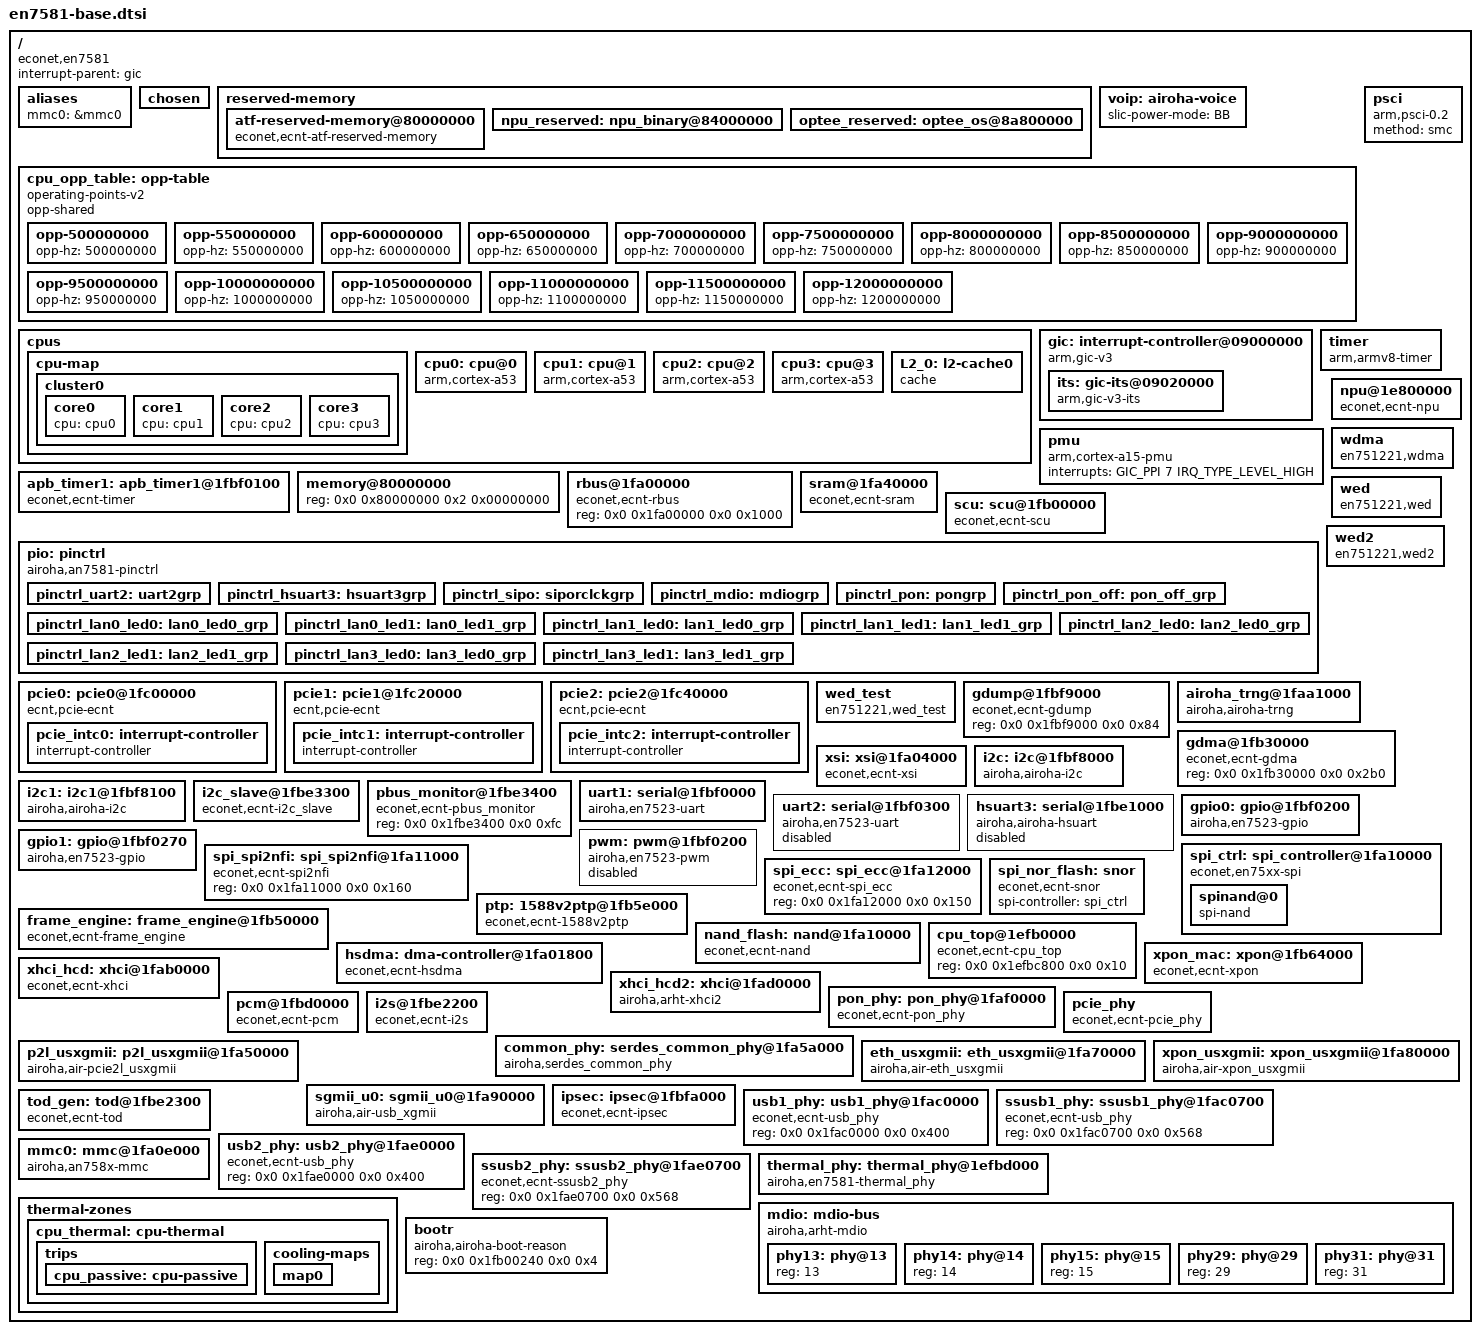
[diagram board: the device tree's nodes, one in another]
#include <dt-bindings/interrupt-controller/irq.h>
#include <dt-bindings/interrupt-controller/arm-gic.h>
#include <dt-bindings/gpio/gpio.h>
#include <dt-bindings/thermal/thermal.h>

/dts-v1/;

/ {
	compatible = "econet,en7581";
	interrupt-parent = <&gic>;
	#address-cells = <2>;
	#size-cells = <2>;

	aliases {
		mmc0 = &mmc0;
	};

	chosen {
		// --- onu_type ---
		// xPON ONU Type, 0--unknown, 1--SFU, 2--HGU, [7:4], 0x0--Auto, 0x1:GPON, 0x2:EPON, 0x3:XEPON_10G_1G,
		// 0x4:XEPON_10G_10G, 0x5:XEPON_1G_1G, 0x6:XGPON, 0x7:XGSPON...
		//
		// --- qdma_init ---
		// EN7580 QDMA init setting
		// [1:0], 0x0--qdma_lan payload size 2k, 0x1--qdma_lan 1k, 0x2--qdma_lan 512, 0x3--qdma_lan 256
		// [2], reserve
		// [3], 0x0--qdma_lan dscp in DRAM, 0x1--qdma_lan dscp in SRAM
		// [5:4], 0x0--qdma_wan payload size 2k, 0x1--qdma_wan 1k, 0x2--qdma_wan 512, 0x3--qdma_wan 256
		// [6], reserve
		// [7], 0x0--qdma_wan dscp in DRAM, 0x1--qdma_wan dscp in SRAM
		// default set: qdma_lan in SRAM, 256Byte payload; qdma_wan in DRAM, 256Byte payload
		// [8], 0 -- Wan(GDM2,PON/ATM/PTM..) slow path  1 -- fast path
		// [9], 0 -- Lan(GDM1,GSW) slow path  1 -- fast path
		// [10], 0 -- XSI PCIE0 slow path  1 -- fast path
		// [11], 0 -- XSI PCIE1 slow path  1 -- fast path
		// [12], 0 -- XSI USB slow path  1 -- fast path
		// [13], 0 -- XSI ETHER slow path  1 -- fast path
		// [14], 0 -- XSI PON slow path  1 -- fast path
		// [15], 0 -- XSI PCIE0 not care   1 -- direct to GDM
		// [16], 0 -- XSI PCIE1 not care   1 -- direct to GDM
		// [17], 0 -- XSI USB not care   1 -- direct to GDM
		// [18], 0 -- XSI ETHER not care   1 -- direct to GDM
		// [19], 0 -- XSI PON not care   1 -- direct to GDM
		//
		// --- serdes_pon ---
		// PON Serdes selection setting, serdes_sel is hex value
		// first digit is etherLAN or etherWAN select
		// 0: for NONE
		// 1: for etherLAN
		// 2: for etherWAN
		// second digit is serdes interface select
		// 0: for PON
		// 1: for XFI
		// 2: for USXGMII
		// 3: for HSGMII
		// 4: for PD(power down serdes)
		//
		// --- serdes_ethernet ---
		// Ethernet Serdes selection setting, serdes_sel is hex value
		// first digit is etherLAN or etherWAN select
		// 0: for NONE
		// 1: for etherLAN
		// 2: for etherWAN
		// second digit is serdes interface select
		// 0: for XFI
		// 1: for USXGMII
		// 2: for HSGMII
		// 3: for 5G BaseR
		// 4: for PD(power down serdes)
		//
		// --- serdes_wifi1 ---
		// WiFi_1 Serdes selection setting, serdes_sel is hex value
		// first digit is etherLAN or etherWAN select
		// 0: for NONE
		// 1: for etherLAN
		// 2: for etherWAN
		// second digit is serdes interface select
		// 0: for PCIE0 2-LANE
		// 1: for PCIE0 1-LANE
		// 2: for HSGMII
		// 3: for USXGMII
		// 4: for XFI
		// 5: for PD(power down serdes)
		//
		// --- serdes_wifi2 ---
		// WiFi_2 Serdes selection setting, serdes_sel is hex value
		// first digit is etherLAN or etherWAN select
		// 0: for NONE
		// 1: for etherLAN
		// 2: for etherWAN
		// second digit is serdes interface select
		// 0: for PCIE0 2-LANE
		// 1: for PCIE1 1-LANE
		// 2: for HSGMII
		// 3: for USXGMII
		// 4: for XFI
		// 5: for PD(power down serdes)
		//
		// --- serdes_usb1 ---
		// USB_1 Serdes selection setting, serdes_sel is hex value
		// first digit is etherLAN or etherWAN select
		// 0: for NONE
		// 1: for etherLAN
		// 2: for etherWAN
		// second digit is serdes interface select
		// 0: for USB 3.0 MAC
		// 1: for HSGMII
		// 2: for PD(power down serdes)
		//
		// --- serdes_usb2 ---
		// USB_2 Serdes selection setting, serdes_sel is hex value
		// first digit is etherLAN or etherWAN select
		// 0: for NONE
		// 1: for etherLAN
		// 2: for etherWAN
		// second digit is serdes interface select
		// 0: for USB 3.0 MAC
		// 1: for PCIE2 1-LANE
		// 2: for PD(power down serdes)

		bootargs = "console=ttyS0,115200n8 qdma_init=bb onu_type=72 serdes_ethernet=112 serdes_wifi1=01 serdes_wifi2=01 serdes_usb1=00 serdes_usb2=02 serdes_pon=00";
		stdout-path = &uart1;
	};

	reserved-memory {
		#address-cells = <2>;
		#size-cells = <2>;
		ranges;

		atf-reserved-memory@80000000 {
			compatible = "econet,ecnt-atf-reserved-memory";
			no-map;
			reg = <0x0 0x80000000 0x0 0x40000>;
		};

		npu_reserved: npu_binary@84000000 {
			no-map;
			reg = <0x0 0x84000000 0x0 0x100000>;
		};

		optee_reserved: optee_os@8a800000 {
			no-map;
			reg = <0x0 0x8a800000 0x0 0x800000>;
		};

		/* pstore memory reservations */
		#include "en7581-pstore.dtsi"

	};

	voip: airoha-voice {
		// -----------------------------------------------------
		// Slic power mode
		// -----------------------------------------------------
		// Possible values:
		//   BB		- Buck Boost
		//   IB		- Inverting Buck Boost
		//   TB		- Buck-Boost fixed tracker AKA 'Tracker Buck Boost'
		//
		// Notes:
		//   1) If slic power mode set to other non-empty value,
		//      slic modules will NOT be probed/loaded.
		//   2) If slic power mode is not set or set to empty
		//      string then "BB" mode will be used as default
		//   3) voip_loader command line options will override
		//      DTS settings.
		// -----------------------------------------------------
		slic-power-mode = "BB";
	};

	cpu_opp_table: opp-table {
		compatible = "operating-points-v2";
		opp-shared;

		opp-500000000 {
			opp-hz = /bits/ 64 <500000000>;
		};

		opp-550000000 {
			opp-hz = /bits/ 64 <550000000>;
		};

		opp-600000000 {
			opp-hz = /bits/ 64 <600000000>;
		};

		opp-650000000 {
			opp-hz = /bits/ 64 <650000000>;
		};

		opp-7000000000 {
			opp-hz = /bits/ 64 <700000000>;
		};

		opp-7500000000 {
			opp-hz = /bits/ 64 <750000000>;
		};

		opp-8000000000 {
			opp-hz = /bits/ 64 <800000000>;
		};

		opp-8500000000 {
			opp-hz = /bits/ 64 <850000000>;
		};

		opp-9000000000 {
			opp-hz = /bits/ 64 <900000000>;
		};

		opp-9500000000 {
			opp-hz = /bits/ 64 <950000000>;
		};

		opp-10000000000 {
			opp-hz = /bits/ 64 <1000000000>;
		};

		opp-10500000000 {
			opp-hz = /bits/ 64 <1050000000>;
		};

		opp-11000000000 {
			opp-hz = /bits/ 64 <1100000000>;
		};

		opp-11500000000 {
			opp-hz = /bits/ 64 <1150000000>;
		};

		opp-12000000000 {
			opp-hz = /bits/ 64 <1200000000>;
		};
	};

	psci {
		compatible = "arm,psci-0.2";
		method = "smc";
	};

	cpus {
		#address-cells = <1>;
		#size-cells = <0>;

		cpu-map {
			cluster0 {
				core0 {
					cpu = <&cpu0>;
				};
				core1 {
					cpu = <&cpu1>;
				};
				core2 {
					cpu = <&cpu2>;
				};
				core3 {
					cpu = <&cpu3>;
				};
			};
		};

		cpu0: cpu@0 {
			device_type = "cpu";
			compatible = "arm,cortex-a53";
			reg = <0x0>;
			operating-points-v2 = <&cpu_opp_table>;
			enable-method = "psci";
			clock-frequency = <80000000>;
			next-level-cache = <&L2_0>;
			#cooling-cells = <2>;
		};

		cpu1: cpu@1 {
			device_type = "cpu";
			compatible = "arm,cortex-a53";
			reg = <0x1>;
			operating-points-v2 = <&cpu_opp_table>;
			enable-method = "psci";
			clock-frequency = <80000000>;
			next-level-cache = <&L2_0>;
			#cooling-cells = <2>;
		};

		cpu2: cpu@2 {
			device_type = "cpu";
			compatible = "arm,cortex-a53";
			reg = <0x2>;
			operating-points-v2 = <&cpu_opp_table>;
			enable-method = "psci";
			clock-frequency = <80000000>;
			next-level-cache = <&L2_0>;
			#cooling-cells = <2>;
		};

		cpu3: cpu@3 {
			device_type = "cpu";
			compatible = "arm,cortex-a53";
			reg = <0x3>;
			operating-points-v2 = <&cpu_opp_table>;
			enable-method = "psci";
			clock-frequency = <80000000>;
			next-level-cache = <&L2_0>;
			#cooling-cells = <2>;
		};

		L2_0: l2-cache0 {
			compatible = "cache";
		};
	};

	gic: interrupt-controller@09000000 {
		compatible = "arm,gic-v3";
		interrupt-controller;
		#interrupt-cells = <3>;
		#address-cells = <1>;
		#size-cells = <1>;
		reg = <0x0 0x09000000 0x0 0x20000>,
		      <0x0 0x09080000 0x0 0x80000>;
		interrupts = <GIC_PPI 9 IRQ_TYPE_LEVEL_LOW>;

		its: gic-its@09020000 {
			compatible = "arm,gic-v3-its";
			msi-controller;
			#msi-cell = <1>;
			reg = <0x0 0x090200000 0x0 0x20000>;
		};
	};


	timer {
		compatible = "arm,armv8-timer";
		interrupt-parent = <&gic>;
		interrupts = <GIC_PPI 13 (GIC_CPU_MASK_SIMPLE(4) | IRQ_TYPE_LEVEL_LOW)>,
			     <GIC_PPI 14 (GIC_CPU_MASK_SIMPLE(4) | IRQ_TYPE_LEVEL_LOW)>,
			     <GIC_PPI 11 (GIC_CPU_MASK_SIMPLE(4) | IRQ_TYPE_LEVEL_LOW)>,
			     <GIC_PPI 10 (GIC_CPU_MASK_SIMPLE(4) | IRQ_TYPE_LEVEL_LOW)>;
		clock-frequency = <25000000>;
	};

	pmu {
		//compatible = "arm,armv8-pmuv3";
		compatible = "arm,cortex-a15-pmu";
		interrupts = <GIC_PPI 7 IRQ_TYPE_LEVEL_HIGH>;
	};

	npu@1e800000 {
		compatible = "econet,ecnt-npu";
		reg = <0x0 0x1e800000 0x0 0x78000>,	//NPU 480K SRAM
		      <0x0 0x1e900000 0x0 0x313000>;	//NPU 32K SRAM, registers
		memory-region = <&npu_reserved>;
		interrupts = <GIC_SPI 118 IRQ_TYPE_LEVEL_HIGH>,
			     <GIC_SPI 119 IRQ_TYPE_LEVEL_HIGH>,
			     <GIC_SPI 120 IRQ_TYPE_LEVEL_HIGH>,
			     <GIC_SPI 121 IRQ_TYPE_LEVEL_HIGH>,
			     <GIC_SPI 122 IRQ_TYPE_LEVEL_HIGH>,
			     <GIC_SPI 123 IRQ_TYPE_LEVEL_HIGH>,
			     <GIC_SPI 125 IRQ_TYPE_LEVEL_HIGH>,	//mbox2host irq
			     <GIC_SPI 103 IRQ_TYPE_LEVEL_HIGH>,	//npu timer0 wdog intr
			     <GIC_SPI 109 IRQ_TYPE_LEVEL_HIGH>,	//npu timer1 wdog intr
			     <GIC_SPI 113 IRQ_TYPE_LEVEL_HIGH>,	//npu timer2 wdog intr
			     <GIC_SPI 117 IRQ_TYPE_LEVEL_HIGH>,	//npu timer3 wdog intr
			     <GIC_SPI 134 IRQ_TYPE_LEVEL_HIGH>,	//npu timer4 wdog intr
			     <GIC_SPI 135 IRQ_TYPE_LEVEL_HIGH>,	//npu timer5 wdog intr
			     <GIC_SPI 136 IRQ_TYPE_LEVEL_HIGH>,	//npu timer6 wdog intr
			     <GIC_SPI 137 IRQ_TYPE_LEVEL_HIGH>;	//npu timer7 wdog intr
	};

	apb_timer1: apb_timer1@1fbf0100 {
		compatible = "econet,ecnt-timer";
		reg = <0x0 0x1fbf0100 0x0 0x40>;
		interrupts = <GIC_SPI 20 IRQ_TYPE_LEVEL_HIGH>,
			     <GIC_SPI 21 IRQ_TYPE_LEVEL_HIGH>,
			     <GIC_SPI 22 IRQ_TYPE_LEVEL_HIGH>,
			     <GIC_SPI 25 IRQ_TYPE_LEVEL_HIGH>;
	};

	memory@80000000 {
		device_type = "memory";
		reg = <0x0 0x80000000 0x2 0x00000000>;
	};

	rbus@1fa00000 {
		compatible = "econet,ecnt-rbus";
		reg = <0x0 0x1fa00000 0x0 0x1000>;		//RBus Core
	};

	sram@1fa40000 {
		compatible = "econet,ecnt-sram";
		reg = <0x0 0x1fa40000 0x0 0x8000>,		//GDMP SRAM
		      <0x0 0x08000000 0x0 0x40000>,		//L2C SRAM (only for CPU internal access)
		      <0x0 0x1EFC0000 0x0 0x40000>,		//L2C SRAM (only for CPU/NPU/GDMA/SPI/Crypto/WOE external access via pbus)
		      <0x0 0x1E880000 0x0 0x40000>,		//L2C SRAM (only for CPU/NPU/HSDMA/PCIE external access via npu_rbus)
		      <0x0 0x1fbe3000 0x0 0x200>;		//I2C_SLAVE SRAM
	};

	scu: scu@1fb00000 {
		bootph-all;
		compatible = "econet,ecnt-scu";
			// ------------------------------------------------------------
			// WARNING:
			// ------------------------------------------------------------
			//   1) [dirty hack] NP SCU iomem region length was reduced
			//	to avoid conflicts with "airoha-boot-reason" driver. This
			//	does NOT breaks "ecnt-scu" driver because mapping of the
			//	iomem area actually provide access not only to the
			//	specified area, but to the whole page, so all regs are
			//	still accessible.
			//   2) Actual NP SCU iomem area is:
			//	  <0x1fb00000 0x960>,	//NP SCU
			// ------------------------------------------------------------
		reg = <0x0 0x1fb00000 0x0 0x4>,		//NP SCU
			// ------------------------------------------------------------
			// WARNING:
			// ------------------------------------------------------------
			//   1) [dirty hack] Chip SCU iomem region length was reduced
			//	to avoid conflicts with "en7523-pinctrl" driver. This
			//	does NOT breaks "ecnt-scu" driver because mapping of the
			//	iomem area actually provide access not only to the
			//	specified area, but to the whole page, so all regs are
			//	still accessible.
			//   2) Function is_pinctrl_reg() was added to "ecnt-scu" driver
			//	to check access and prevent writing to pinctrl registers.
			//	Please keep in sync this function with "en7523-pinctrl"
			//	driver.
			//   3) Actual Chip SCU iomem area is:
			//	  <0x1fa20000 0x360>,	//CHIP SCU
			// ------------------------------------------------------------
			<0x0 0x1fa20000 0x0 0x4>,		//CHIP SCU
			<0x0 0x1fa2FF30 0x0 0x10>;		//Rbus clk ctl for FPGA
		interrupts = <GIC_SPI 47 IRQ_TYPE_LEVEL_HIGH>;
	};

	pio: pinctrl {
		compatible = "airoha,an7581-pinctrl";
		// --------------------------------------------------------------------
		// WARNING:
		// --------------------------------------------------------------------
		//   1) iomem regions used by this driver overlaps with iomem region
		//	used by "ecnt-scu" driver. Dirty hack (see scu@1fb00000 dts
		//	section) was introduced to make "ecnt-scu" and "an7581-pinctrl"
		//	coexisting.
		//   2) Please keep in sync iomem areas used by this driver with
		//	is_pinctrl_reg() function from the "ecnt-scu" driver.
		// --------------------------------------------------------------------
		reg = <0x0 0x1fa20214 0x0 0x20>, /* IOMUX Control Registers */
			<0x0 0x1fa2001C 0x0 0x18>, /* IO TX Driving Control Registers */
			<0x0 0x1fa20044 0x0 0x18>, /* IO Pull up/down Control Registers */
			<0x0 0x1fa2027C 0x0 0x8>;  /* LED Mapping Register */

		pinctrl_uart2: uart2grp {
			function = "uart2";
			groups = "uart2_grp";
		};

		pinctrl_hsuart3: hsuart3grp {
			function = "hsuart3";
			groups = "hsuart3_grp";
		};

		pinctrl_sipo: siporclckgrp {
			function = "sipo_rclk";
			groups = "sipo_rclk_grp";
		};

		pinctrl_mdio: mdiogrp {
			function = "mdio";
			groups = "mdio_grp";
		};

		pinctrl_pon: pongrp {
			function = "pon0";
			groups = "pon0_grp";
		};

		pinctrl_pon_off: pon_off_grp {
			function = "pon0_off";
			groups = "pon0_grp";
		};

		pinctrl_lan0_led0: lan0_led0_grp {
			function = "lan0_led0";
			groups = "lan0_led0_grp";
		};

		pinctrl_lan0_led1: lan0_led1_grp {
			function = "lan0_led1";
			groups = "lan0_led1_grp";
		};

		pinctrl_lan1_led0: lan1_led0_grp {
			function = "lan1_led0";
			groups = "lan1_led0_grp";
		};

		pinctrl_lan1_led1: lan1_led1_grp {
			function = "lan1_led1";
			groups = "lan1_led1_grp";
		};

		pinctrl_lan2_led0: lan2_led0_grp {
			function = "lan2_led0";
			groups = "lan2_led0_grp";
		};

		pinctrl_lan2_led1: lan2_led1_grp {
			function = "lan2_led1";
			groups = "lan2_led1_grp";
		};

		pinctrl_lan3_led0: lan3_led0_grp {
			function = "lan3_led0";
			groups = "lan3_led0_grp";
		};

		pinctrl_lan3_led1: lan3_led1_grp {
			function = "lan3_led1";
			groups = "lan3_led1_grp";
		};
	};

	pcie0: pcie0@1fc00000 {
		device_type = "pci";
		compatible = "ecnt,pcie-ecnt";
		reg = <0x0 0x1fc00000 0x0 0x20000>;
		reg-names = "pcie-mac";

		#address-cells = <3>;
		#size-cells = <2>;
		interrupts = <GIC_SPI 39 IRQ_TYPE_LEVEL_HIGH>;  //23+16
		bus-range = <0x00 0xff>;
		ranges = <0x02000000 0 0x20000000 0x0 0x20000000 0 0x4000000>;

		#interrupt-cells = <1>;
		interrupt-map-mask = <0 0 0 7>;
		interrupt-map = <0 0 0 1 &pcie_intc0 1>,
				<0 0 0 2 &pcie_intc0 2>,
				<0 0 0 3 &pcie_intc0 3>,
				<0 0 0 4 &pcie_intc0 4>;

		pcie_intc0: interrupt-controller {
			interrupt-controller;
			#address-cells = <0>;
			#interrupt-cells = <1>;
		};
	};

	pcie1: pcie1@1fc20000 {
		device_type = "pci";
		compatible = "ecnt,pcie-ecnt";
		reg = <0x0 0x1fc20000 0x0 0x20000>;
		reg-names = "pcie-mac";

		#address-cells = <3>;
		#size-cells = <2>;
		interrupts = <GIC_SPI 40 IRQ_TYPE_LEVEL_HIGH>;  //24+16
		bus-range = <0x00 0xff>;
		ranges = <0x02000000 0 0x24000000 0x0 0x24000000 0 0x4000000>;

		#interrupt-cells = <1>;
		interrupt-map-mask = <0 0 0 7>;
		interrupt-map = <0 0 0 1 &pcie_intc1 1>,
				<0 0 0 2 &pcie_intc1 2>,
				<0 0 0 3 &pcie_intc1 3>,
				<0 0 0 4 &pcie_intc1 4>;

		pcie_intc1: interrupt-controller {
			interrupt-controller;
			#address-cells = <0>;
			#interrupt-cells = <1>;
		};
	};

	pcie2: pcie2@1fc40000 {
		device_type = "pci";
		compatible = "ecnt,pcie-ecnt";
		reg = <0x0 0x1fc40000 0x0 0x20000>;
		reg-names = "pcie-mac";

		#address-cells = <3>;
		#size-cells = <2>;
		interrupts = <GIC_SPI 41 IRQ_TYPE_LEVEL_HIGH>;  //25+16
		bus-range = <0x00 0xff>;
		ranges = <0x02000000 0 0x28000000 0x0 0x28000000 0 0x4000000>;

		#interrupt-cells = <1>;
		interrupt-map-mask = <0 0 0 7>;
		interrupt-map = <0 0 0 1 &pcie_intc2 1>,
				<0 0 0 2 &pcie_intc2 2>,
				<0 0 0 3 &pcie_intc2 3>,
				<0 0 0 4 &pcie_intc2 4>;

		pcie_intc2: interrupt-controller {
			interrupt-controller;
			#address-cells = <0>;
			#interrupt-cells = <1>;
		};
	};

	wdma{
		compatible = "en751221,wdma";
		reg = <0x0 0x1fa06000 0x0 0x400 >,
		      <0x0 0x1fa06400 0x0 0x400 >;
		interrupts = <GIC_SPI 69 IRQ_TYPE_LEVEL_HIGH>,
			     <GIC_SPI 70 IRQ_TYPE_LEVEL_HIGH>,
			     <GIC_SPI 71 IRQ_TYPE_LEVEL_HIGH>,
			     <GIC_SPI 72 IRQ_TYPE_LEVEL_HIGH>,
			     <GIC_SPI 73 IRQ_TYPE_LEVEL_HIGH>,
			     <GIC_SPI 74 IRQ_TYPE_LEVEL_HIGH>;
	};

	wed{
		compatible = "en751221,wed";
		wed_num = <2>;
		pci_slot_map = <0>, <1>;
		reg = <0x0 0x1fa02000 0x0 0xb00 >,
		      <0x0 0x1fa03000 0x0 0xb00 >;
		interrupts = <GIC_SPI 67 IRQ_TYPE_LEVEL_HIGH>,
			     <GIC_SPI 68 IRQ_TYPE_LEVEL_HIGH>;
	};

	wed2{
		compatible = "en751221,wed2";
		wed_num = <2>;
		pci_slot_map = <0>, <1>;
		reg = <0x0 0x1fa02000 0x0 0xb00 >,
		      <0x0 0x1fa03000 0x0 0xb00 >;
		interrupts = <GIC_SPI 67 IRQ_TYPE_LEVEL_HIGH>,
			     <GIC_SPI 68 IRQ_TYPE_LEVEL_HIGH>;
	};

	wed_test{
		compatible = "en751221,wed_test";
		wed_num = <2>;
		reg = <0x0 0x1fa02b00 0x0 0x100 >,
		      <0x0 0x1fa03b00 0x0 0x100 >;
	};

	gdump@1fbf9000 {
		compatible = "econet,ecnt-gdump";
		reg = <0x0 0x1fbf9000 0x0 0x84>;
	};

	airoha_trng@1faa1000 {
		compatible = "airoha,airoha-trng";
		reg = <0x0 0x1faa1000 0x0 0xc04>;
		interrupts = <GIC_SPI 35 IRQ_TYPE_LEVEL_HIGH>;
	};

	gdma@1fb30000 {
		compatible = "econet,ecnt-gdma";
		reg = <0x0 0x1fb30000 0x0 0x2b0>;
	};

	xsi: xsi@1fa04000 {
		compatible = "econet,ecnt-xsi";
		reg = <0x0 0x1fa08000 0x0 0x300>,	//hsgmii ae
		      <0x0 0x1fa04000 0x0 0x300>,	//hsgmii pcie0
		      <0x0 0x1fa05000 0x0 0x300>,	//hsgmii pcie1
		      <0x0 0x1fa07000 0x0 0x300>,	//hsgmii usb
		      <0x0 0x1fa09000 0x0 0x300>;	//eth usb
	};

	i2c: i2c@1fbf8000 {
		compatible = "airoha,airoha-i2c";
		reg = <0x0 0x1fbf8000 0x0 0x65>;
		clock-frequency = <400000>;
	};

	i2c1: i2c1@1fbf8100 {
		compatible = "airoha,airoha-i2c";
		reg = <0x0 0x1fbf8100 0x0 0x65>;
		clock-frequency = <400000>;
	};

	i2c_slave@1fbe3300 {
		compatible = "econet,ecnt-i2c_slave";
		reg = <0x0 0x1fbe3300 0x0 0x10>;
		dev0_addr = <0x60>;
		dev1_addr = <0x62>;
		interrupts = <GIC_SPI 28 IRQ_TYPE_LEVEL_HIGH>;
	};

	pbus_monitor@1fbe3400 {
		compatible = "econet,ecnt-pbus_monitor";
		reg = <0x0 0x1fbe3400 0x0 0xfc>;
	};

	uart1: serial@1fbf0000 {
		bootph-all;
		compatible = "airoha,en7523-uart";
		reg = <0x0 0x1fbf0000 0x0 0x30>;
		reg-io-width = <4>;
		reg-shift = <2>;
		interrupts = <GIC_SPI 18 IRQ_TYPE_LEVEL_HIGH>;
		clock-frequency = <1843200>;
		status = "okay";
	};

	uart2: serial@1fbf0300 {
		compatible = "airoha,en7523-uart";
		reg = <0x0 0x1fbf0300 0x0 0x30>,
		      <0x0 0x1fbf0600 0x0 0x30>,
		      <0x0 0x1fbf0700 0x0 0x30>;
		reg-io-width = <4>;
		reg-shift = <2>;
		interrupts = <GIC_SPI 32 IRQ_TYPE_LEVEL_HIGH>,
			     <GIC_SPI 61 IRQ_TYPE_LEVEL_HIGH>,
			     <GIC_SPI 62 IRQ_TYPE_LEVEL_HIGH>;
		clock-frequency = <7372800>;
		pinctrl-names = "default";
		pinctrl-0 = <&pinctrl_uart2>;
		status = "disabled";
	};

	hsuart3: serial@1fbe1000 {
		compatible = "airoha,airoha-hsuart";
		reg = <0x0 0x1fbe1000 0x0 0x40>;
		reg-io-width = <4>;
		reg-shift = <2>;
		interrupts = <GIC_SPI 54 IRQ_TYPE_LEVEL_HIGH>;
		clock-frequency = <7372800>;
		pinctrl-names = "default";
		pinctrl-0 = <&pinctrl_hsuart3>;
		status = "disabled";
	};

	gpio0: gpio@1fbf0200 {
		compatible = "airoha,en7523-gpio";
		airoha,bank-name = "gpio_a";	/* u-boot specific */
		reg = <0x0 0x1fbf0204 0x0 0x4>,
		      <0x0 0x1fbf0200 0x0 0x4>,
		      <0x0 0x1fbf0220 0x0 0x4>,
		      <0x0 0x1fbf0214 0x0 0x4>,
		      <0x0 0x1fbf0208 0x0 0x4>, /* Interrupt status register */
		      <0x0 0x1fbf0210 0x0 0x4>, /* Level 0 */
		      <0x0 0x1fbf028C 0x0 0x4>, /* Level 1 */
		      <0x0 0x1fbf020C 0x0 0x4>, /* Edge 0 */
		      <0x0 0x1fbf0280 0x0 0x4>; /* Edge 1 */
		gpio-controller;
		#gpio-cells = <2>;
		interrupt-controller;
		#interrupt-cells = <2>;
		interrupt-parent = <&gic>;
		interrupts = <GIC_SPI 26 IRQ_TYPE_LEVEL_HIGH>;
		status = "okay";
	};

	gpio1: gpio@1fbf0270 {
		compatible = "airoha,en7523-gpio";
		airoha,bank-name = "gpio_b";	/* u-boot specific */
		reg = <0x0 0x1fbf0270 0x0 0x4>,
		      <0x0 0x1fbf0260 0x0 0x4>,
		      <0x0 0x1fbf0264 0x0 0x4>,
		      <0x0 0x1fbf0278 0x0 0x4>,
		      <0x0 0x1fbf027C 0x0 0x4>, /* Interrupt status register */
		      <0x0 0x1fbf0290 0x0 0x4>, /* Level 0 */
		      <0x0 0x1fbf0294 0x0 0x4>, /* Level 1 */
		      <0x0 0x1fbf0284 0x0 0x4>, /* Edge 0 */
		      <0x0 0x1fbf0288 0x0 0x4>; /* Edge 1 */
		gpio-controller;
		#gpio-cells = <2>;
		interrupt-controller;
		#interrupt-cells = <2>;
		interrupt-parent = <&gic>;
		interrupts = <GIC_SPI 26 IRQ_TYPE_LEVEL_HIGH>;
		status = "okay";
	};

	pwm: pwm@1fbf0200 {
		compatible = "airoha,en7523-pwm";
		reg = <0x0 0x1fbf0234 0x0 0x4>, /* Flash mode cfg */
		      <0x0 0x1fbf023C 0x0 0x4>, /* Flash period set 0 */
		      <0x0 0x1fbf0240 0x0 0x4>, /* Flash period set 1 */
		      <0x0 0x1fbf0244 0x0 0x4>, /* Flash period set 2 */
		      <0x0 0x1fbf0248 0x0 0x4>, /* Flash period set 3 */
		      <0x0 0x1fbf024C 0x0 0x4>, /* Flash map cfg 0 */
		      <0x0 0x1fbf0250 0x0 0x4>, /* Flash map cfg 1 */
		      <0x0 0x1fbf0298 0x0 0x4>, /* Cycle cfg value 0 */
		      <0x0 0x1fbf029C 0x0 0x4>, /* Cycle cfg value 1 */
		      <0x0 0x1fbf0230 0x0 0x4>, /* SIPO Flash mode cfg */
		      <0x0 0x1fbf0254 0x0 0x4>, /* SIPO Flash map cfg 0 */
		      <0x0 0x1fbf0258 0x0 0x4>, /* SIPO Flash map cfg 1 */
		      <0x0 0x1fbf025C 0x0 0x4>, /* SIPO Flash map cfg 2 */
		      <0x0 0x1fbf0224 0x0 0x4>, /* SIPO LED data */
		      <0x0 0x1fbf0228 0x0 0x4>, /* SIPO clock divisor */
		      <0x0 0x1fbf022C 0x0 0x4>; /* SIPO clock delay */
		/*hc74595;*/
		#pwm-cells = <3>;
		pinctrl-names = "default";
		pinctrl-0 = <&pinctrl_sipo>;
		status = "disabled";
	};

	spi_ctrl: spi_controller@1fa10000 {
		bootph-all;
		compatible = "econet,en75xx-spi";
		#address-cells = <1>;
		#size-cells = <0>;
		reg = <0x0 0x1fa10000 0x0 0x140>,		//SPI Controller Base
		      <0x0 0x00000000 0x0 0x1000>;		//SPI Controller auto read interrupt test
		interrupts = <GIC_SPI 51 IRQ_TYPE_LEVEL_HIGH>;

		scu     = <&scu>;
		spi2nfi = <&spi_spi2nfi>;
		spi-ecc = <&spi_ecc>;

		spinand@0 {
			bootph-all;
			compatible = "spi-nand";
			reg = <0x0>;			// Chip select
			spi-tx-bus-width = <2>;
			spi-rx-bus-width = <2>;
			spi-max-frequency = <50000000>;
		};
	};

	spi_spi2nfi: spi_spi2nfi@1fa11000 {
		bootph-all;
		compatible = "econet,ecnt-spi2nfi";
		reg = <0x0 0x1fa11000 0x0 0x160>;	//NFI2SPI
	};

	spi_ecc: spi_ecc@1fa12000 {
		bootph-all;
		compatible = "econet,ecnt-spi_ecc";
		reg = <0x0 0x1fa12000 0x0 0x150>;	//NFI ECC
	};

	frame_engine: frame_engine@1fb50000 {
		compatible = "econet,ecnt-frame_engine";
		reg = <0x0 0x1fb50000 0x0 0x2600>,	//FE + PPE
		      <0x0 0x1fb54000 0x0 0x4000>,	//QDMA
		      <0x0 0x1fb58000 0x0 0x8000>;	//SWITCH
		interrupts = <GIC_SPI  37 IRQ_TYPE_LEVEL_HIGH>, // QDMA LAN INT1 21+16
			     <GIC_SPI  55 IRQ_TYPE_LEVEL_HIGH>, // QDMA LAN INT2 39+16
			     <GIC_SPI  56 IRQ_TYPE_LEVEL_HIGH>, // QDMA LAN INT3 40+16
			     <GIC_SPI  57 IRQ_TYPE_LEVEL_HIGH>, // QDMA LAN INT4 41+16
			     <GIC_SPI  38 IRQ_TYPE_LEVEL_HIGH>, // QDMA WAN INT1 22+16
			     <GIC_SPI  58 IRQ_TYPE_LEVEL_HIGH>, // QDMA WAN INT2 42+16
			     <GIC_SPI  59 IRQ_TYPE_LEVEL_HIGH>, // QDMA WAN INT3 43+16
			     <GIC_SPI  60 IRQ_TYPE_LEVEL_HIGH>, // QDMA WAN INT4 44+16
			     <GIC_SPI  49 IRQ_TYPE_LEVEL_HIGH>, // FE ERROR INTR 33+16
			     <GIC_SPI  64 IRQ_TYPE_LEVEL_HIGH>, // PDMA INTR 48+16
			     <GIC_SPI 203 IRQ_TYPE_LEVEL_HIGH>, // TDMA INTR0 187+16
			     <GIC_SPI 204 IRQ_TYPE_LEVEL_HIGH>, // TDMA INTR1 188+16
			     <GIC_SPI 205 IRQ_TYPE_LEVEL_HIGH>, // TDMA INTR2 189+16
			     <GIC_SPI 206 IRQ_TYPE_LEVEL_HIGH>, // TDMA INTR3 190+16
			     <GIC_SPI 207 IRQ_TYPE_LEVEL_HIGH>, // TDMA INTR4 191+16
			     <GIC_SPI 208 IRQ_TYPE_LEVEL_HIGH>, // TDMA INTR5 192+16
			     <GIC_SPI 209 IRQ_TYPE_LEVEL_HIGH>, // TDMA INTR6 193+16
			     <GIC_SPI 210 IRQ_TYPE_LEVEL_HIGH>; // TDMA INTR7 194+16
	};

	ptp: 1588v2ptp@1fb5e000 {
		compatible = "econet,ecnt-1588v2ptp";
		reg = <0x0 0x1fb5e000 0x0 0xcc>,   //[1] gsw_ptp
		      <0x0 0x1fa09500 0x0 0x200>,  //[2] xfi_mac_ptp
		      <0x0 0x1fa08500 0x0 0x200>;  //[3] xfi_mac_pon_ptp
		interrupts = <GIC_SPI  31 IRQ_TYPE_LEVEL_HIGH>,  // 15+16 = 31  [1] gsw_ptp
			     <GIC_SPI  65 IRQ_TYPE_LEVEL_HIGH>,  // 49+16 = 65  [2] xfi_mac_ptp
			     <GIC_SPI 147 IRQ_TYPE_LEVEL_HIGH>;  // 131+16= 147 [3] xfi_mac_pon_ptp
	};

	spi_nor_flash: snor {
		compatible = "econet,ecnt-snor";
		spi-controller = <&spi_ctrl>;
	};

	nand_flash: nand@1fa10000 {
		compatible = "econet,ecnt-nand";
		spi-controller = <&spi_ctrl>;
		spi2nfi = <&spi_spi2nfi>;
		spi-ecc = <&spi_ecc>;
	};

	hsdma: dma-controller@1fa01800 {
		compatible = "econet,ecnt-hsdma";
		reg = <0x0 0x1fa01800 0x0 0x300>;
		interrupts = <GIC_SPI 63 IRQ_TYPE_LEVEL_HIGH>;
		#dma-cells = <1>;
		dma-channels = <2>;
		dma-requests = <2>;
	};

	cpu_top@1efb0000 {
		compatible = "econet,ecnt-cpu_top";
		reg = <0x0 0x1efbc800 0x0 0x10>;			//CTRL
	};

	xpon_mac: xpon@1fb64000 {
		compatible = "econet,ecnt-xpon";
		reg = <0x0 0x1fb64000 0x0 0x3e8>,
		      <0x0 0x1fb66000 0x0 0x23c>,
		      <0x0 0x1fb65000 0x0 0xFF8>;
		interrupts = <GIC_SPI 42 IRQ_TYPE_LEVEL_HIGH>, // XPON MAC INT 26+16
			     <GIC_SPI 34 IRQ_TYPE_LEVEL_HIGH>; // DYINGGASP INT 18+16
	};

	xhci_hcd: xhci@1fab0000 {
		compatible = "econet,ecnt-xhci";
		reg = <0x0 0x1fab0000 0x0 0x3e00>,	//MAC base address
		      <0x0 0x1fab3e00 0x0 0x100>;	//IPPC base address
		interrupts = <GIC_SPI 33 IRQ_TYPE_LEVEL_HIGH>;
	};

	xhci_hcd2: xhci@1fad0000 {
		compatible = "airoha,arht-xhci2";
		reg = <0x0 0x1fad0000 0x0 0x3e00>,	//MAC base address
		      <0x0 0x1fad3e00 0x0 0x100>;	//IPPC base address
		interrupts = <GIC_SPI 150 IRQ_TYPE_LEVEL_HIGH>;
	};

	pon_phy: pon_phy@1faf0000 {
		compatible = "econet,ecnt-pon_phy";
		reg = <0x0 0x1faf0000 0x0 0x1fff>,			// PON_PHY_ASIC_RG range
		      <0x0 0x1fa2ff24 0x0 0x4>,				// PON_PHY_FPGA_RG_TX_OFF
		      <0x0 0x1faf3000 0x0 0xfff>,			// PON_PHY_ASIC_RG range2
		      <0x0 0x1faf4000 0x0 0xfff>;			// PON_PHY_ASIC_RG range3
		//    <0x0 0x1fa84024 0x0 0x4>,				// PON_PHY_ASIC_RG range4,only for xilinx_fpga
		//    <0x0 0x1fa84030 0x0 0x4>;				// PON_PHY_ASIC_RG range5,only for xilinx_fpga
		// interrupts = <GIC_SPI 43 IRQ_TYPE_LEVEL_HIGH>;	// XPON_PHY_INTR 27+16 move to common
	};

	pcm@1fbd0000 {
		compatible = "econet,ecnt-pcm";
		reg = <0x0 0x1fbd0000 0x0 0x4fff>;
		interrupts = <GIC_SPI 27 IRQ_TYPE_LEVEL_HIGH>;
	};

	i2s@1fbe2200 {
		compatible = "econet,ecnt-i2s";
		reg = <0x0 0x1fbe2200 0x0 0xfc>,
		      <0x0 0x1fbe2e00 0x0 0x114>;
		interrupts = <GIC_SPI 48 IRQ_TYPE_LEVEL_HIGH>;
	};

	pcie_phy: pcie_phy {
		compatible = "econet,ecnt-pcie_phy";
	};

	common_phy: serdes_common_phy@1fa5a000 {
		compatible = "airoha,serdes_common_phy";
		reg = <0x0 0x1fa5a000 0x0 0xfff>,		//PCIEG3_PHY_PMA_PHYA
		      <0x0 0x1fa5b000 0x0 0xfff>,		//PCIEG3_PHY_PMA_PHYD_0
		      <0x0 0x1fa5c000 0x0 0xfff>,		//PCIEG3_PHY_PMA_PHYD_1
		      <0x0 0x1fa7A000 0x0 0xfff>,		//xfi_ana_pxp
		      <0x0 0x1fa7B000 0x0 0xfff>,		//xfi_pma
		      <0x0 0x1fa8A000 0x0 0xfff>,		//pon_ana_pxp
		      <0x0 0x1fa8B000 0x0 0xfff>,		//pon_pma
		      <0x0 0x1fa84000 0x0 0x685>;		//multi_sgmii, PON_PHY_ASIC_RG range4,only for xilinx_fpga, PON_PHY_ASIC_RG range5,only for xilinx_fpga
		interrupts = <GIC_SPI 43 IRQ_TYPE_LEVEL_HIGH>;	// XPON_PHY_INTR 27+16
		int_name = "common_int";
	};

	p2l_usxgmii: p2l_usxgmii@1fa50000 {
		compatible = "airoha,air-pcie2l_usxgmii";
		reg = <0x0 0x1fa55900 0x0 0x334>,		//PCS mode1 range (xfi)
		      <0x0 0x1fa50a00 0x0 0x168>,		//PCS mode2 range (hsgmii)
		      <0x0 0x1fa50000 0x0 0x64>,		//AN range
		      <0x0 0x1fa56000 0x0 0xff>,		//rate adaption range (xgmii)
		//    <0x0 0x1fa76100 0x0 0x204>;		//rate adaption range (mii)
		//    <0x0 0x1fa5A000 0x0 0x171>,		//xfi_ana_pxp
		      <0x0 0x1fa54000 0x0 0x685>,		//multi_sgmii
		//    <0x0 0x1fa5B000 0x0 0x95D>,		//xfi_pma
		      <0x0 0x1fa65900 0x0 0x334>,		//PCS mode1 range (xfi)
		      <0x0 0x1fa60a00 0x0 0x168>,		//PCS mode2 range (hsgmii)
		      <0x0 0x1fa60000 0x0 0x64>,		//AN range
		      <0x0 0x1fa66000 0x0 0xff>,		//rate adaption range (xgmii)
		//    <0x0 0x1fa76100 0x0 0x204>;		//rate adaption range (mii)
		      <0x0 0x1fa64000 0x0 0x685>;		//multi_sgmii
		//    <0x0 0x1fa5C000 0x0 0x95D>;		//l2_xfi_pma

		interrupts = <GIC_SPI 151 IRQ_TYPE_LEVEL_HIGH>;
		int_name = "p2l_usxgmii";
		int_id = <0>;
	};

	eth_usxgmii: eth_usxgmii@1fa70000 {
		compatible = "airoha,air-eth_usxgmii";
		reg = <0x0 0x1fa75900 0x0 0x334>,		//PCS mode1 range (xfi)
		      <0x0 0x1fa70a00 0x0 0x168>,		//PCS mode2 range (hsgmii)
		      <0x0 0x1fa70000 0x0 0x64>,		//AN range
		      <0x0 0x1fa76000 0x0 0xff>,		//rate adaption range (xgmii)
		//    <0x0 0x1fa76100 0x0 0x204>;		//rate adaption range (mii)
		//    <0x0 0x1fa7A000 0x0 0x171>,		//xfi_ana_pxp
		      <0x0 0x1fa74000 0x0 0x685>;		//multi_sgmii
		//    <0x0 0x1fa7B000 0x0 0x95D>;		//xfi_pma

		interrupts = <GIC_SPI 66 IRQ_TYPE_LEVEL_HIGH>;
		int_name = "eth_usxgmii";
		int_id = <0>;
	};

	xpon_usxgmii: xpon_usxgmii@1fa80000 {
		compatible = "airoha,air-xpon_usxgmii";
		reg = <0x0 0x1fa85900 0x0 0x334>,		//PCS mode1 range (xfi)
		      <0x0 0x1fa80a00 0x0 0x168>,		//PCS mode2 range (hsgmii)
		      <0x0 0x1fa80000 0x0 0x64>,		//AN range
		      <0x0 0x1fa86000 0x0 0xff>;		//rate adaption range (xgmii)
		//    <0x0 0x1fa76100 0x0 0x204>;		//rate adaption range (mii)
		//    <0x0 0x1fa8A000 0x0 0x171>,		//xfi_ana_pxp
		//    <0x0 0x1fa84000 0x0 0x685>;		//multi_sgmii
		//    <0x0 0x1fa8B000 0x0 0x95D>;		//xfi_pma

		//interrupts = <GIC_SPI 43 IRQ_TYPE_LEVEL_HIGH>;
		int_name = "xpon_usxgmii";
		int_id = <0>;
	};

	sgmii_u0: sgmii_u0@1fa90000 {
		compatible = "airoha,air-usb_xgmii";
		reg = <0x0 0x1fa90a00 0x0 0x168>,		//pcs
		      <0x0 0x1fa90000 0x0 0x64>,		//AN range
		      <0x0 0x1fa96000 0x0 0xff>,		//RA
		      <0x0 0x1fa9a000 0x0 0x401>,		//Qphy(multi phy_ana)
		      <0x0 0x1fa94000 0x0 0x401>;		//multi sgmii

		interrupts = <GIC_SPI 153 IRQ_TYPE_LEVEL_HIGH>;	// usb_hsgmii INT 137+16
		int_name = "sgmii_usb0";
		int_id = <0>;					// usb always is 2
	};

	ipsec: ipsec@1fbfa000 {
		compatible = "econet,ecnt-ipsec";
		reg = <0x0 0x1fbfa000 0x0 0x268>;
		interrupts = <GIC_SPI 79 IRQ_TYPE_LEVEL_HIGH>; // IPSEC_INTR 63+16
	};

	tod_gen: tod@1fbe2300 {
		compatible = "econet,ecnt-tod";
		reg = <0x0 0x1fbe2300 0x0 0xD0>;
		interrupts = <GIC_SPI 78 IRQ_TYPE_LEVEL_HIGH>; // TOD GEN INT 62+16
	};

	usb1_phy: usb1_phy@1fac0000 {
		compatible = "econet,ecnt-usb_phy";
		reg = <0x0 0x1fac0000 0x0 0x400>;		//USB20 on port USB1 RG range
	};

	ssusb1_phy: ssusb1_phy@1fac0700 {
		compatible = "econet,ecnt-usb_phy";
		reg = <0x0 0x1fac0700 0x0 0x568>;		//SSUSB on port USB1 RG range
	};

	usb2_phy: usb2_phy@1fae0000 {
		compatible = "econet,ecnt-usb_phy";
		reg = <0x0 0x1fae0000 0x0 0x400>;		//USB20 on port USB2 RG range
	};

	ssusb2_phy: ssusb2_phy@1fae0700 {
		compatible = "econet,ecnt-ssusb2_phy";
		reg = <0x0 0x1fae0700 0x0 0x568>;		//SSUSB on port USB2 RG range
	};

	mmc0: mmc@1fa0e000 {
		bootph-all;
		compatible = "airoha,an758x-mmc";
		reg = <0x0 0x1fa0e000 0x0 0x1000>,
		      <0x0 0x1fa0c000 0x0 0x60>;
		interrupts = <GIC_SPI 170 IRQ_TYPE_LEVEL_HIGH>;
		source-clock-frequency = <200000000>;
		//clocks = <&pericfg CLK_PERI_MSDC30_0_PD>,
		//	 <&topckgen CLK_TOP_MSDC50_0_SEL>;
		//clock-names = "source", "hclk";
		//status = "disabled";
		bus-width = <4>;
		max-frequency = <52000000>;			//FPGA: max value is host->src_clk_freq/2
								//ASIC: max value is 52MHz
		disable-wp;
		cap-mmc-highspeed;
		//mmc-ddr-3_3v;
		non-removable;
	};

	thermal_phy: thermal_phy@1efbd000 {
		#thermal-sensor-cells = <0>;
		compatible = "airoha,en7581-thermal_phy";
		reg = <0x0 0x1efbd000 0x0 0x0fff>;		// ptp_thermal_ctrl
		int_name = "ptp_therm";
	};

	mdio: mdio-bus {
		compatible = "airoha,arht-mdio";
		phy13: phy@13 {
			reg = <13>;
		};
		phy14: phy@14 {
			reg = <14>;
		};
		phy15: phy@15 {
			reg = <15>;
		};
		phy29: phy@29 {
			reg = <29>;
		};
		phy31: phy@31 {
			reg = <31>;
		};
	};

	thermal-zones {
		cpu_thermal: cpu-thermal {
			polling-delay-passive = <200>;
			polling-delay = <1000>;
			thermal-sensors = <&thermal_phy 0>;
			trips {
				cpu_passive: cpu-passive {
					temperature = <105000>;
					hysteresis = <0>;
					type = "passive";
				};
			};
			cooling-maps {
				map0 {
					trip = <&cpu_passive>;
					cooling-device = <&cpu0 THERMAL_NO_LIMIT THERMAL_NO_LIMIT>,
							 <&cpu1 THERMAL_NO_LIMIT THERMAL_NO_LIMIT>,
							 <&cpu2 THERMAL_NO_LIMIT THERMAL_NO_LIMIT>,
							 <&cpu3 THERMAL_NO_LIMIT THERMAL_NO_LIMIT>;
				};
			};
		};
	};

	bootr {
		compatible = "airoha,airoha-boot-reason";
		// --------------------------------------------------------------------
		// WARNING:
		// --------------------------------------------------------------------
		//   1) iomem regions used by this driver overlaps with iomem region
		//	used by "ecnt-scu" driver. Dirty hack (see scu@1fb00000 dts
		//	section) was introduced to make "ecnt-scu" and "an7581-pinctrl"
		//	coexisting. The same is used for this driver.
		reg = <0x0 0x1fb00240 0x0 0x4>;
	};
};
